# SGX_PRM register map
Vendor: Texas Instruments
Peripheral module from a debugger description file (folder omap4460).
Registers are 32-bit, access not given, reset 0x30000 unless marked. A register's access mark holds for its fields unless they carry their own. Offsets are as the file gives them; lines under a group give offsets from that group; [hi:lo] are bit positions; {n}, {i} and the like mark numbered series; 'fields as' and 'values as' point back to an identical list; <NAME> marks a mode.

## SGX_PRM
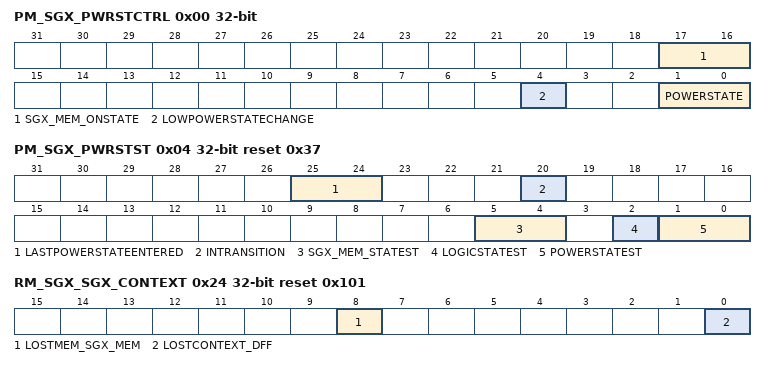
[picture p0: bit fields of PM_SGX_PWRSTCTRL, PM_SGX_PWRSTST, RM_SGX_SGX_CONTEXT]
0x00 PM_SGX_PWRSTCTRL — This register controls the SGX power state to reach upon a domain sleep transition
  [17:16] SGX_MEM_ONSTATE — SGX_MEM memory bank state when domain is ON. (access R Rreturns1s)
    3=SGX_MEM_ONSTATE_3_r (Memory bank is on when the domain is ON.)
  [4] LOWPOWERSTATECHANGE — Power state change request when domain has already performed a sleep transition. Allows going into deeper low power state without waking up the power domain. (access RW WSpecial)
    0=Do not request a low power state change; 1=Request a low power state change. This bit is automatically cleared when the power state is effectively changed or when power state is ON.
  [1:0] POWERSTATE rw — Power state control
    0=OFF state; 2=INACTIVE state; 3=ON State
0x04 PM_SGX_PWRSTST reset 0x37 — This register provides a status on the current SGX power domain state. [warm reset insensitive]
  [25:24] LASTPOWERSTATEENTERED — Last low power state entered. Set to 0x3 upon write of the same only. This register is intended for debug purpose only. (access RW W1toSet)
    0=LASTPOWERSTATEENTERED_0_r (Power domain was previously OFF); 1=LASTPOWERSTATEENTERED_1_r (Power domain was previously in RETENTION); 2=LASTPOWERSTATEENTERED_2_r (Power domain was previously ON-INACTIVE); 3=LASTPOWERSTATEENTERED_3_r (Power domain was previously ON-ACTIVE)
  [20] INTRANSITION ro — Domain transition status
    0=INTRANSITION_0_r (No ongoing transition on power domain); 1=INTRANSITION_1_r (Power domain transition is in progress.)
  [5:4] SGX_MEM_STATEST ro — SGX_MEM memory bank state status
    0=SGX_MEM_STATEST_0_r (Memory is OFF); 1=SGX_MEM_STATEST_1_r (Reserved); 2=SGX_MEM_STATEST_2_r (Reserved); 3=SGX_MEM_STATEST_3_r (Memory is ON)
  [2] LOGICSTATEST ro — Logic state status
    0=LOGICSTATEST_0_r (Logic in domain is OFF); 1=LOGICSTATEST_1_r (Logic in domain is ON)
  [1:0] POWERSTATEST ro — Current power state status
    0=POWERSTATEST_0_r (Power domain is OFF); 1=POWERSTATEST_1_r (Power domain is in RETENTION); 2=POWERSTATEST_2_r (Power domain is ON-INACTIVE); 3=POWERSTATEST_3_r (Power domain is ON-ACTIVE)
0x24 RM_SGX_SGX_CONTEXT reset 0x101 — This register contains dedicated SGX context statuses. [warm reset insensitive]
  [8] LOSTMEM_SGX_MEM — Specify if memory-based context in SGX_MEM memory bank has been lost due to a previous power transition or other reset source. (access RW W1toClr)
    0=Context has been maintained; 1=Context has been lost
  [0] LOSTCONTEXT_DFF — Specify if DFF-based context has been lost due to a previous power transition or other reset source. (set upon assertion of SGX_RST signal) (access RW W1toClr)
    0=Context has been maintained; 1=Context has been lost
